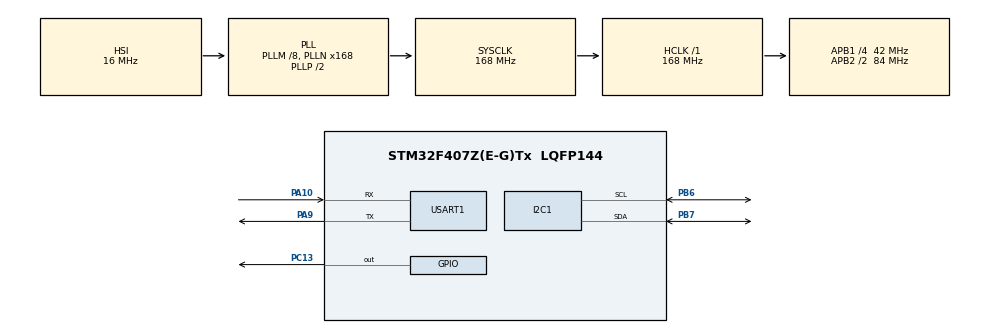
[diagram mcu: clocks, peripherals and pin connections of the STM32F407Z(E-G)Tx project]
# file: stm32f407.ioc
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Dma.Request0=USART1_TX
Dma.USART1_TX.0.Direction=DMA_MEMORY_TO_PERIPH
Dma.USART1_TX.0.FIFOMode=DMA_FIFOMODE_DISABLE
Dma.USART1_TX.0.Instance=DMA2_Stream7
Dma.USART1_TX.0.MemDataAlignment=DMA_MDATAALIGN_BYTE
Dma.USART1_TX.0.MemInc=DMA_MINC_ENABLE
Dma.USART1_TX.0.Mode=DMA_NORMAL
Dma.USART1_TX.0.PeriphDataAlignment=DMA_PDATAALIGN_BYTE
Dma.USART1_TX.0.PeriphInc=DMA_PINC_DISABLE
Dma.USART1_TX.0.Priority=DMA_PRIORITY_LOW
Mcu.Family=STM32F4
Mcu.Name=STM32F407Z(E-G)Tx
Mcu.Package=LQFP144
NVIC.DMA2_Stream7_IRQn=true\:0\:0\:false\:false\:true\:false\:true\:true
NVIC.I2C1_ER_IRQn=true\:0\:0\:false\:false\:true\:true\:true\:true
NVIC.I2C1_EV_IRQn=true\:0\:0\:false\:false\:true\:true\:true\:true
NVIC.PriorityGroup=NVIC_PRIORITYGROUP_4
NVIC.USART1_IRQn=true\:0\:0\:false\:false\:true\:false\:true\:true
PA10.Mode=Asynchronous
PA10.Signal=USART1_RX
PA13.Mode=Serial_Wire
PA13.Signal=SYS_JTMS-SWDIO
PA14.Mode=Serial_Wire
PA14.Signal=SYS_JTCK-SWCLK
PA9.Mode=Asynchronous
PA9.Signal=USART1_TX
PB6.Mode=I2C
PB6.Signal=I2C1_SCL
PB7.Mode=I2C
PB7.Signal=I2C1_SDA
PC13-ANTI_TAMP.PinState=GPIO_PIN_SET
PC13-ANTI_TAMP.Signal=GPIO_Output
PH0-OSC_IN.Mode=HSE-External-Oscillator
PH0-OSC_IN.Signal=RCC_OSC_IN
PH1-OSC_OUT.Mode=HSE-External-Oscillator
PH1-OSC_OUT.Signal=RCC_OSC_OUT
ProjectManager.HeapSize=0x200
ProjectManager.StackSize=0x400
ProjectManager.TargetToolchain=MDK-ARM V5.32
RCC.48MHZClocksFreq_Value=84000000
RCC.AHBFreq_Value=168000000
RCC.APB1CLKDivider=RCC_HCLK_DIV4
RCC.APB1Freq_Value=42000000
RCC.APB1TimFreq_Value=84000000
RCC.APB2CLKDivider=RCC_HCLK_DIV2
RCC.APB2Freq_Value=84000000
RCC.APB2TimFreq_Value=168000000
RCC.CortexFreq_Value=168000000
RCC.HCLKFreq_Value=168000000
RCC.HSE_VALUE=25000000
RCC.HSI_VALUE=16000000
RCC.LSE_VALUE=32768
RCC.PLLM=8
RCC.PLLN=168
RCC.SYSCLKFreq_VALUE=168000000
RCC.SYSCLKSource=RCC_SYSCLKSOURCE_PLLCLK
RCC.VCOOutputFreq_Value=336000000
USART1.VirtualMode=VM_ASYNC
board=custom

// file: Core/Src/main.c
/* USER CODE BEGIN Header */
/**
  ******************************************************************************
  * @file           : main.c
  * @brief          : Main program body
  ******************************************************************************
  * @attention
  *
  * Copyright (c) 2026 STMicroelectronics.
  * All rights reserved.
  *
  * This software is licensed under terms that can be found in the LICENSE file
  * in the root directory of this software component.
  * If no LICENSE file comes with this software, it is provided AS-IS.
  *
  ******************************************************************************
  */
/* USER CODE END Header */
#include "main.h"
#include "dma.h"
#include "i2c.h"
#include "usart.h"
#include "gpio.h"

/* USER CODE BEGIN Includes */
#include "Printf_DMA.H"	//导入串口打印的头文件
#include "SCD40.H"			//导入二氧化碳传感器的头文件
/* USER CODE END Includes */

void SystemClock_Config(void);

/* USER CODE BEGIN 0 */
SCD40_Data_TypeDef SCD40_Data1={0};
/* USER CODE END 0 */

int main(void)
{

  /* MCU Configuration--------------------------------------------------------*/

  /* Reset of all peripherals, Initializes the Flash interface and the Systick. */
  HAL_Init();

  /* Configure the system clock */
  SystemClock_Config();

  /* Initialize all configured peripherals */
  MX_GPIO_Init();
  MX_DMA_Init();
  MX_USART1_UART_Init();
  MX_I2C1_Init();
  /* USER CODE BEGIN 2 */
	SCD40_Init();		//二氧化碳传感器初始化
  /* USER CODE END 2 */

  /* Infinite loop */
  /* USER CODE BEGIN WHILE */
  while (1)
  {
//		//单片机测试代码
//		HAL_GPIO_WritePin(GPIOC,GPIO_PIN_13,GPIO_PIN_SET);
//		HAL_Delay(500);
//		HAL_GPIO_WritePin(GPIOC,GPIO_PIN_13,GPIO_PIN_RESET);
//		HAL_Delay(500);

		// //串口打印测试代码
		// printf_dma("hhh");

		//读取二氧化碳传感器的数据
		SCD40_Read_Data(&SCD40_Data1);

    //数据结构
    // //存储传感器数据的结构体
    // typedef struct{
    // 	uint16_t	CO2;					//CO2浓度的成员，单位ppm
    // 	uint8_t		Temperature;	//温度成员变量，单位摄氏度oC
    // 	uint8_t		Humidity;			//湿度成员结构体变量，单位%
    // }SCD40_Data_TypeDef;

    printf_dma("CO2: %d ppm\r\n",SCD40_Data1.CO2);  								//打印二氧化碳浓度
    printf_dma("Temperature: %d oC\r\n",SCD40_Data1.Temperature);  	//打印温度
    printf_dma("Humidity: %d %%\r\n",SCD40_Data1.Humidity);  				//打印湿度
    printf_dma("\r\n");  																						//打印换行,隔离每组数据
    HAL_Delay(500);  //延时500ms

    /* USER CODE END WHILE */

  }
}

void SystemClock_Config(void)
{
  RCC_OscInitTypeDef RCC_OscInitStruct = {0};
  RCC_ClkInitTypeDef RCC_ClkInitStruct = {0};

  /** Configure the main internal regulator output voltage
  */
  __HAL_RCC_PWR_CLK_ENABLE();
  __HAL_PWR_VOLTAGESCALING_CONFIG(PWR_REGULATOR_VOLTAGE_SCALE1);

  /** Initializes the RCC Oscillators according to the specified parameters
  * in the RCC_OscInitTypeDef structure.
  */
  RCC_OscInitStruct.OscillatorType = RCC_OSCILLATORTYPE_HSI;
  RCC_OscInitStruct.HSIState = RCC_HSI_ON;
  RCC_OscInitStruct.HSICalibrationValue = RCC_HSICALIBRATION_DEFAULT;
  RCC_OscInitStruct.PLL.PLLState = RCC_PLL_ON;
  RCC_OscInitStruct.PLL.PLLSource = RCC_PLLSOURCE_HSI;
  RCC_OscInitStruct.PLL.PLLM = 8;
  RCC_OscInitStruct.PLL.PLLN = 168;
  RCC_OscInitStruct.PLL.PLLP = RCC_PLLP_DIV2;
  RCC_OscInitStruct.PLL.PLLQ = 4;
  if (HAL_RCC_OscConfig(&RCC_OscInitStruct) != HAL_OK)
  {
    Error_Handler();
  }

  /** Initializes the CPU, AHB and APB buses clocks
  */
  RCC_ClkInitStruct.ClockType = RCC_CLOCKTYPE_HCLK|RCC_CLOCKTYPE_SYSCLK
                              |RCC_CLOCKTYPE_PCLK1|RCC_CLOCKTYPE_PCLK2;
  RCC_ClkInitStruct.SYSCLKSource = RCC_SYSCLKSOURCE_PLLCLK;
  RCC_ClkInitStruct.AHBCLKDivider = RCC_SYSCLK_DIV1;
  RCC_ClkInitStruct.APB1CLKDivider = RCC_HCLK_DIV4;
  RCC_ClkInitStruct.APB2CLKDivider = RCC_HCLK_DIV2;

  if (HAL_RCC_ClockConfig(&RCC_ClkInitStruct, FLASH_LATENCY_5) != HAL_OK)
  {
    Error_Handler();
  }
}

void Error_Handler(void)
{
  __disable_irq();
  while (1)
  {
  }
}
